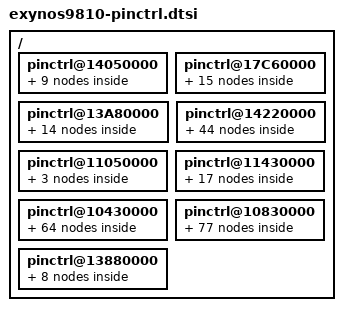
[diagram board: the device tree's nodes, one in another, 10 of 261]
/*
 * Samsung's Exynos9810 SoC pin-mux and pin-config device tree source
 *
 * Copyright (c) 2017 Samsung Electronics Co., Ltd.
 *		http://www.samsung.com
 *
 * Samsung's Exynos9810 SoC pin-mux and pin-config options are listed as device
 * tree nodes are listed in this file.
 *
 * This program is free software; you can redistribute it and/or modify
 * it under the terms of the GNU General Public License version 2 as
 * published by the Free Software Foundation.
*/

/ {
	/* ALIVE */
	pinctrl@14050000 {
		gpa0: gpa0 {
			gpio-controller;
			#gpio-cells = <2>;

			interrupt-controller;
			#interrupt-cells = <3>;
			interrupt-parent = <&gic>;
			interrupts = <0 36 0>, <0 37 0>, <0 38 0>, <0 39 0>,
				     <0 40 0>, <0 41 0>, <0 42 0>, <0 43 0>;
		};

		gpa1: gpa1 {
			gpio-controller;
			#gpio-cells = <2>;

			interrupt-controller;
			#interrupt-cells = <3>;
			interrupt-parent = <&gic>;
			interrupts = <0 44 0>, <0 45 0>, <0 46 0>, <0 47 0>,
				     <0 48 0>, <0 49 0>, <0 50 0>, <0 51 0>;
		};

		gpa2: gpa2 {
			gpio-controller;
			#gpio-cells = <2>;

			interrupt-controller;
			#interrupt-cells = <3>;
			interrupt-parent = <&gic>;
			interrupts = <0 52 0>, <0 53 0>, <0 54 0>, <0 55 0>,
				     <0 56 0>, <0 57 0>, <0 58 0>, <0 59 0>;
		};

		gpa3: gpa3 {
			gpio-controller;
			#gpio-cells = <2>;

			interrupt-controller;
			#interrupt-cells = <3>;
			interrupt-parent = <&gic>;
			interrupts = <0 60 0>, <0 61 0>, <0 62 0>, <0 63 0>,
				     <0 64 0>, <0 65 0>, <0 66 0>, <0 67 0>;
		};

		gpq0: gpq0 {
			gpio-controller;
			#gpio-cells = <2>;

			interrupt-controller;
			#interrupt-cells = <2>;
		};

		gpa4: gpa4 {
			gpio-controller;
			#gpio-cells = <2>;

			interrupt-controller;
			#interrupt-cells = <3>;
			interrupt-parent = <&gic>;
			interrupts = <0 INTREQ__EINT32 0>, <0 INTREQ__EINT33 0>;
		};

		speedy_bus: speedy-bus {
			samsung,pins = "gpq0-4";
			samsung,pin-function = <2>;
			samsung,pin-pud = <3>;
			samsung,pin-drv = <0>;
		};

		uart1_bus_single: uart1-bus {
			samsung,pins = "gpq0-3", "gpq0-2", "gpq0-1", "gpq0-0";
			samsung,pin-function = <2>;
			samsung,pin-pud = <0>;
		};

		uart1_bus_rts: uart1-bus-rts {
			samsung,pins = "gpq0-2";
			samsung,pin-function = <1>;
			samsung,pin-pud = <0>;
			samsung,pin-val = <1>;
		};

	};

	/* AUD */
	pinctrl@17C60000 {
		gpb0: gpb0 {
			gpio-controller;
			#gpio-cells = <2>;

			interrupt-controller;
			#interrupt-cells = <2>;
		};

		gpb1: gpb1 {
			gpio-controller;
			#gpio-cells = <2>;

			interrupt-controller;
			#interrupt-cells = <2>;
		};

		gpb2: gpb2 {
			gpio-controller;
			#gpio-cells = <2>;

			interrupt-controller;
			#interrupt-cells = <2>;
		};

		aud_codec_mclk: aud-codec-mclk {
			samsung,pins = "gpb0-0";
			samsung,pin-function = <2>;
			samsung,pin-pud = <1>;
		};

		aud_codec_mclk_idle: aud-codec-mclk-idle {
			samsung,pins = "gpb0-0";
			samsung,pin-function = <0>;
			samsung,pin-pud = <1>;
		};

		aud_i2s0_bus: aud-i2s0-bus {
			samsung,pins = "gpb0-1", "gpb0-2", "gpb0-3", "gpb0-4";
			samsung,pin-function = <2>;
			samsung,pin-pud = <1>;
		};

		aud_i2s0_idle: aud-i2s0-idle {
			samsung,pins = "gpb0-1", "gpb0-2", "gpb0-3", "gpb0-4";
			samsung,pin-function = <0>;
			samsung,pin-pud = <1>;
		};

		aud_i2s1_bus: aud-i2s1-bus {
			samsung,pins = "gpb1-0", "gpb1-1", "gpb1-2", "gpb1-3";
			samsung,pin-function = <2>;
			samsung,pin-pud = <1>;
		};

		aud_i2s1_idle: aud-i2s1-idle {
			samsung,pins = "gpb1-0", "gpb1-1", "gpb1-2", "gpb1-3";
			samsung,pin-function = <0>;
			samsung,pin-pud = <1>;
		};

		aud_i2s2_bus: aud-i2s2-bus {
			samsung,pins = "gpb1-4", "gpb1-5", "gpb1-6", "gpb1-7";
			samsung,pin-function = <2>;
			samsung,pin-pud = <1>;
		};

		aud_i2s2_idle: aud-i2s2-idle {
			samsung,pins = "gpb1-4", "gpb1-5", "gpb1-6", "gpb1-7";
			samsung,pin-function = <0>;
			samsung,pin-pud = <1>;
		};

		aud_dsd_bus: aud-dsd-bus {
			samsung,pins = "gpb1-4", "gpb1-5", "gpb1-6";
			samsung,pin-function = <3>;
			samsung,pin-pud = <1>;
		};

		aud_dsd_idle: aud-dsd-idle {
			samsung,pins = "gpb1-4", "gpb1-5", "gpb1-6";
			samsung,pin-function = <0>;
			samsung,pin-pud = <1>;
		};

		aud_i2s3_bus: aud-i2s3_bus {
			samsung,pins = "gpb2-0", "gpb2-1", "gpb2-2", "gpb2-3";
			samsung,pin-function = <2>;
			samsung,pin-pud = <1>;
		};

		aud_i2s3_idle: aud-i2s3-idle {
			samsung,pins = "gpb2-0", "gpb2-1", "gpb2-2", "gpb2-3";
			samsung,pin-function = <0>;
			samsung,pin-pud = <1>;
		};
	};

	/* CHUB */
	pinctrl@13A80000 {
		gph0: gph0 {
			gpio-controller;
			#gpio-cells = <2>;

			interrupt-controller;
			#interrupt-cells = <2>;
		};

		gph1: gph1 {
			gpio-controller;
			#gpio-cells = <2>;

			interrupt-controller;
			#interrupt-cells = <2>;
		};

		/* USI_CHUB 00 */
		hsi2c42_bus: hsi2c42-bus {
			samsung,pins = "gph0-0", "gph0-1";
			samsung,pin-function = <2>;
			samsung,pin-pud = <0>;
			samsung,pin-drv = <0>;
		};

		/* USI_CHUB00_I2C */
		hsi2c43_bus: hsi2c43-bus {
			samsung,pins = "gph0-2", "gph0-3";
			samsung,pin-function = <3>;
			samsung,pin-pud = <0>;
			samsung,pin-drv = <0>;
		};

		/* USI_CHUB 01 */
		hsi2c44_bus: hsi2c44-bus {
			samsung,pins = "gph0-4", "gph0-5";
			samsung,pin-function = <2>;
			samsung,pin-pud = <0>;
			samsung,pin-drv = <0>;
		};

		/* USI_CHUB01_I2C */
		hsi2c45_bus: hsi2c45-bus {
			samsung,pins = "gph0-6", "gph0-7";
			samsung,pin-function = <3>;
			samsung,pin-pud = <0>;
			samsung,pin-drv = <0>;
		};

		/* USI_CHUB00_UART */
		uart21_bus_single: uart21-bus {
			samsung,pins = "gph0-0", "gph0-1", "gph0-2", "gph-3";
			samsung,pin-function = <2>;
			samsung,pin-pud = <0>;
		};

		/* USI_CHUB01_UART */
		uart22_bus_single: uart22-bus {
			samsung,pins = "gph0-4", "gph0-5", "gph0-6", "gph-7";
			samsung,pin-function = <2>;
			samsung,pin-pud = <0>;
		};

		/* SPI USI_CHUB00 */
		spi20_bus: spi20-bus {
			samsung,pins = "gph0-0", "gph0-1", "gph0-2";
			samsung,pin-function = <2>;
			samsung,pin-pud = <3>;
			samsung,pin-drv = <0>;
		};

		spi20_cs: spi20-cs {
			samsung,pins = "gph0-3";
			samsung,pin-function = <1>;
			samsung,pin-pud = <3>;
			samsung,pin-drv = <0>;
		};

		spi20_cs_func: spi20-cs-func {
			samsung,pins = "gph0-3";
			samsung,pin-function = <2>;
			samsung,pin-pud = <3>;
			samsung,pin-drv = <0>;
		};

		/* SPI USI_CHUB01 */
		spi21_bus: spi21-bus {
			samsung,pins = "gph0-4", "gph0-5", "gph0-6";
			samsung,pin-function = <2>;
			samsung,pin-pud = <3>;
			samsung,pin-drv = <0>;
		};

		spi21_cs: spi21-cs {
			samsung,pins = "gph0-7";
			samsung,pin-function = <1>;
			samsung,pin-pud = <3>;
			samsung,pin-drv = <0>;
		};

		spi21_cs_func: spi21-cs-func {
			samsung,pins = "gph0-7";
			samsung,pin-function = <2>;
			samsung,pin-pud = <3>;
			samsung,pin-drv = <0>;
		};
	};

	/* CMGP */
	pinctrl@14220000 {
		gpm0: gpm0 {
			gpio-controller;
			#gpio-cells = <2>;

			interrupt-controller;
			#interrupt-cells = <3>;
			interrupt-parent = <&gic>;
			interrupts = <0 9 0>;
		};

		gpm1: gpm1 {
			gpio-controller;
			#gpio-cells = <2>;

			interrupt-controller;
			#interrupt-cells = <3>;
			interrupt-parent = <&gic>;
			interrupts = <0 10 0>;
		};

		gpm2: gpm2 {
			gpio-controller;
			#gpio-cells = <2>;

			interrupt-controller;
			#interrupt-cells = <3>;
			interrupt-parent = <&gic>;
			interrupts = <0 11 0>;
		};

		gpm3: gpm3 {
			gpio-controller;
			#gpio-cells = <2>;

			interrupt-controller;
			#interrupt-cells = <3>;
			interrupt-parent = <&gic>;
			interrupts = <0 12 0>;
		};

		gpm4: gpm4 {
			gpio-controller;
			#gpio-cells = <2>;

			interrupt-controller;
			#interrupt-cells = <3>;
			interrupt-parent = <&gic>;
			interrupts = <0 13 0>;
		};

		gpm5: gpm5 {
			gpio-controller;
			#gpio-cells = <2>;

			interrupt-controller;
			#interrupt-cells = <3>;
			interrupt-parent = <&gic>;
			interrupts = <0 14 0>;
		};

		gpm6: gpm6 {
			gpio-controller;
			#gpio-cells = <2>;

			interrupt-controller;
			#interrupt-cells = <3>;
			interrupt-parent = <&gic>;
			interrupts = <0 15 0>;
		};

		gpm7: gpm7 {
			gpio-controller;
			#gpio-cells = <2>;

			interrupt-controller;
			#interrupt-cells = <3>;
			interrupt-parent = <&gic>;
			interrupts = <0 16 0>;
		};

		gpm10: gpm10 {
			gpio-controller;
			#gpio-cells = <2>;

			interrupt-controller;
			#interrupt-cells = <3>;
			interrupt-parent = <&gic>;
			interrupts = <0 17 0>;
		};

		gpm11: gpm11 {
			gpio-controller;
			#gpio-cells = <2>;


			interrupt-controller;
			#interrupt-cells = <3>;
			interrupt-parent = <&gic>;
			interrupts = <0 18 0>;
		};

		gpm12: gpm12 {
			gpio-controller;
			#gpio-cells = <2>;

			interrupt-controller;
			#interrupt-cells = <3>;
			interrupt-parent = <&gic>;
			interrupts = <0 19 0>;
		};

		gpm13: gpm13 {
			gpio-controller;
			#gpio-cells = <2>;

			interrupt-controller;
			#interrupt-cells = <3>;
			interrupt-parent = <&gic>;
			interrupts = <0 20 0>;
		};

		gpm14: gpm14 {
			gpio-controller;
			#gpio-cells = <2>;

			interrupt-controller;
			#interrupt-cells = <3>;
			interrupt-parent = <&gic>;
			interrupts = <0 21 0>;
		};

		gpm15: gpm15 {
			gpio-controller;
			#gpio-cells = <2>;

			interrupt-controller;
			#interrupt-cells = <3>;
			interrupt-parent = <&gic>;
			interrupts = <0 22 0>;
		};

		gpm16: gpm16 {
			gpio-controller;
			#gpio-cells = <2>;

			interrupt-controller;
			#interrupt-cells = <3>;
			interrupt-parent = <&gic>;
			interrupts = <0 23 0>;
		};

		gpm17: gpm17 {
			gpio-controller;
			#gpio-cells = <2>;

			interrupt-controller;
			#interrupt-cells = <3>;
			interrupt-parent = <&gic>;
			interrupts = <0 24 0>;
		};

		gpm40: gpm40 {
			gpio-controller;
			#gpio-cells = <2>;


			interrupt-controller;
			#interrupt-cells = <3>;
			interrupt-parent = <&gic>;
			interrupts = <0 25 0>;
		};

		gpm41: gpm41 {
			gpio-controller;
			#gpio-cells = <2>;

			interrupt-controller;
			#interrupt-cells = <3>;
			interrupt-parent = <&gic>;
			interrupts = <0 26 0>;
		};

		gpm42: gpm42 {
			gpio-controller;
			#gpio-cells = <2>;

			interrupt-controller;
			#interrupt-cells = <3>;
			interrupt-parent = <&gic>;
			interrupts = <0 27 0>;
		};

		gpm43: gpm43 {
			gpio-controller;
			#gpio-cells = <2>;

			interrupt-controller;
			#interrupt-cells = <3>;
			interrupt-parent = <&gic>;
			interrupts = <0 28 0>;
		};

		/* USI_CMGP00 */
		hsi2c34_bus: hsi2c34-bus {
			samsung,pins = "gpm0-0", "gpm1-0";
			samsung,pin-function = <2>;
			samsung,pin-pud = <0>;
			samsung,pin-drv = <0>;
		};

		/* USI_CMGP00_I2C */
		hsi2c35_bus: hsi2c35-bus {
			samsung,pins = "gpm2-0", "gpm3-0";
			samsung,pin-function = <3>;
			samsung,pin-pud = <0>;
			samsung,pin-drv = <0>;
		};

		/* USI_CMGP01 */
		hsi2c36_bus: hsi2c36-bus {
			samsung,pins = "gpm4-0", "gpm5-0";
			samsung,pin-function = <2>;
			samsung,pin-pud = <0>;
			samsung,pin-drv = <0>;
		};

		/* USI_CMGP01_I2C */
		hsi2c37_bus: hsi2c37-bus {
			samsung,pins = "gpm6-0", "gpm7-0";
			samsung,pin-function = <3>;
			samsung,pin-pud = <0>;
			samsung,pin-drv = <0>;
		};

		/* USI_CMGP02 */
		hsi2c38_bus: hsi2c38-bus {
			samsung,pins = "gpm10-0", "gpm11-0";
			samsung,pin-function = <2>;
			samsung,pin-pud = <0>;
			samsung,pin-drv = <0>;
		};

		/* USI_CMGP02_I2C */
		hsi2c39_bus: hsi2c39-bus {
			samsung,pins = "gpm12-0", "gpm13-0";
			samsung,pin-function = <3>;
			samsung,pin-pud = <0>;
			samsung,pin-drv = <0>;
		};

		/* USI_CMGP03 */
		hsi2c40_bus: hsi2c40-bus {
			samsung,pins = "gpm14-0", "gpm15-0";
			samsung,pin-function = <2>;
			samsung,pin-pud = <0>;
			samsung,pin-drv = <0>;
		};

		/* USI_CMGP03_I2C */
		hsi2c41_bus: hsi2c41-bus {
			samsung,pins = "gpm16-0", "gpm17-0";
			samsung,pin-function = <3>;
			samsung,pin-pud = <0>;
			samsung,pin-drv = <0>;
		};

		/* SPI USI_CMGP00 */
		spi16_bus: spi16-bus {
			samsung,pins = "gpm0-0", "gpm1-0", "gpm2-0";
			samsung,pin-function = <2>;
			samsung,pin-pud = <3>;
			samsung,pin-drv = <0>;
		};

		spi16_cs: spi16-cs {
			samsung,pins = "gpm3-0";
			samsung,pin-function = <1>;
			samsung,pin-pud = <3>;
			samsung,pin-drv = <0>;
		};

		spi16_cs_func: spi16-cs-func {
			samsung,pins = "gpm3-0";
			samsung,pin-function = <2>;
			samsung,pin-pud = <3>;
			samsung,pin-drv = <0>;
		};

		/* SPI USI_CMGP01 */
		spi17_bus: spi17-bus {
			samsung,pins = "gpm4-0", "gpm5-0", "gpm6-0";
			samsung,pin-function = <2>;
			samsung,pin-pud = <3>;
			samsung,pin-drv = <0>;
		};

		spi17_cs: spi17-cs {
			samsung,pins = "gpm7-0";
			samsung,pin-function = <1>;
			samsung,pin-pud = <3>;
			samsung,pin-drv = <0>;
		};

		spi17_cs_func: spi17-cs-func {
			samsung,pins = "gpm7-0";
			samsung,pin-function = <2>;
			samsung,pin-pud = <3>;
			samsung,pin-drv = <0>;
		};

		/* SPI USI_CMGP02 */
		spi18_bus: spi18-bus {
			samsung,pins = "gpm10-0", "gpm11-0", "gpm12-0";
			samsung,pin-function = <2>;
			samsung,pin-pud = <3>;
			samsung,pin-drv = <0>;
		};

		spi18_cs: spi18-cs {
			samsung,pins = "gpm13-0";
			samsung,pin-function = <1>;
			samsung,pin-pud = <3>;
			samsung,pin-drv = <0>;
		};

		spi18_cs_func: spi18-cs-func {
			samsung,pins = "gpm13-0";
			samsung,pin-function = <2>;
			samsung,pin-pud = <3>;
			samsung,pin-drv = <0>;
		};

		/* SPI USI_CMGP03 */
		spi19_bus: spi19-bus {
			samsung,pins = "gpm14-0", "gpm15-0", "gpm16-0";
			samsung,pin-function = <2>;
			samsung,pin-pud = <3>;
			samsung,pin-drv = <0>;
		};

		spi19_cs: spi19-cs {
			samsung,pins = "gpm17-0";
			samsung,pin-function = <1>;
			samsung,pin-pud = <3>;
			samsung,pin-drv = <0>;
		};

		spi19_cs_func: spi19-cs-func {
			samsung,pins = "gpm17-0";
			samsung,pin-function = <2>;
			samsung,pin-pud = <3>;
			samsung,pin-drv = <0>;
		};

		/* USI_CMGP00_UART */
		uart17_bus_single: uart17-bus {
			samsung,pins = "gpm0-0", "gpm1-0", "gpm2-0", "gpm3-0";
			samsung,pin-function = <2>;
			samsung,pin-pud = <0>;
		};

		/* USI_CMGP01_UART */
		uart18_bus_single: uart18-bus {
			samsung,pins = "gpm4-0", "gpm5-0", "gpm6-0", "gpm7-0";
			samsung,pin-function = <2>;
			samsung,pin-pud = <0>;
		};

		/* USI_CMGP02_UART */
		uart19_bus_single: uart19-bus {
			samsung,pins = "gpm10-0", "gpm11-0", "gpm12-0", "gpm13-0";
			samsung,pin-function = <2>;
			samsung,pin-pud = <0>;
		};

		/* USI_CMGP03_UART */
		uart20_bus_single: uart20-bus {
			samsung,pins = "gpm14-0", "gpm15-0", "gpm16-0", "gpm17-0";
			samsung,pin-function = <2>;
			samsung,pin-pud = <0>;
		};

	};

	/* FSYS0 */
	pinctrl@11050000 {
		gpf0: gpf0 {
			gpio-controller;
			#gpio-cells = <2>;

			interrupt-controller;
			#interrupt-cells = <2>;
		};

		ufs_rst_n: ufs-rst-n {
			samsung,pins = "gpf0-1";
			samsung,pin-function = <2>;
			samsung,pin-pud = <0>;
			samsung,pin-con-pdn = <3>;
		};

		ufs_refclk_out: ufs-refclk-out {
			samsung,pins = "gpf0-0";
			samsung,pin-function = <2>;
			samsung,pin-pud = <0>;
			samsung,pin-con-pdn = <3>;
		};
	};

	/* FSYS1 */
	pinctrl@11430000 {
		gpf1: gpf1 {
			gpio-controller;
			#gpio-cells = <2>;

			interrupt-controller;
			#interrupt-cells = <2>;
		};
		gpf2: gpf2 {
			gpio-controller;
			#gpio-cells = <2>;

			interrupt-controller;
			#interrupt-cells = <2>;
		};

		sd2_clk: sd2-clk {
			samsung,pins = "gpf1-0";
			samsung,pin-function = <2>;
			samsung,pin-pud = <0>;
			samsung,pin-drv = <2>;
		};

		sd2_cmd: sd2-cmd {
			samsung,pins = "gpf1-1";
			samsung,pin-function = <2>;
			samsung,pin-pud = <3>;
			samsung,pin-drv = <2>;
		};

		sd2_bus1: sd2-bus-width1 {
			samsung,pins = "gpf1-2";
			samsung,pin-function = <2>;
			samsung,pin-pud = <3>;
			samsung,pin-drv = <2>;
		};

		sd2_bus4: sd2-bus-width4 {
			samsung,pins = "gpf1-3", "gpf1-4", "gpf1-5";
			samsung,pin-function = <2>;
			samsung,pin-pud = <3>;
			samsung,pin-drv = <2>;
		};

		sd2_clk_fast_slew_rate_1x: sd2-clk_fast_slew_rate_1x {
			samsung,pins = "gpf1-0";
			samsung,pin-function = <2>;
			samsung,pin-pud = <0>;
			samsung,pin-drv = <0>;
		};

		sd2_clk_fast_slew_rate_1_5x: sd2-clk_fast_slew_rate_1_5x {
			samsung,pins = "gpf1-0";
			samsung,pin-function = <2>;
			samsung,pin-pud = <0>;
			samsung,pin-drv = <1>;
		};

		sd2_clk_fast_slew_rate_2x: sd2-clk_fast_slew_rate_2x {
			samsung,pins = "gpf1-0";
			samsung,pin-function = <2>;
			samsung,pin-pud = <0>;
			samsung,pin-drv = <2>;
		};

		sd2_clk_fast_slew_rate_2_5x: sd2-clk_fast_slew_rate_2_5x {
			samsung,pins = "gpf1-0";
			samsung,pin-function = <2>;
			samsung,pin-pud = <0>;
			samsung,pin-drv = <3>;
		};

		sd2_clk_fast_slew_rate_3x: sd2-clk_fast_slew_rate_3x {
			samsung,pins = "gpf1-0";
			samsung,pin-function = <2>;
			samsung,pin-pud = <0>;
			samsung,pin-drv = <4>;
		};

		sd2_clk_fast_slew_rate_4x: sd2-clk_fast_slew_rate_4x {
			samsung,pins = "gpf1-0";
			samsung,pin-function = <2>;
			samsung,pin-pud = <0>;
			samsung,pin-drv = <5>;
		};

		pcie0_clkreq: pcie0_clkreq {
			samsung,pins = "gpf2-0";
			samsung,pin-function = <2>;
			samsung,pin-pud = <3>;
			samsung,pin-drv = <3>;
			samsung,pin-con-pdn = <3>;
			samsung,pin-pud-pdn = <3>;
		};

		pcie0_clkreq_output: pcie0_clkreq_output {
			samsung,pins = "gpf2-0";
			samsung,pin-function = <1>;
			samsung,pin-pud = <3>;
			samsung,pin-drv = <3>;
			samsung,pin-con-pdn = <3>;
			samsung,pin-pud-pdn = <3>;
			samsung,pin-val = <1>;
		};

		pcie0_perst: pcie0_perst {
			samsung,pins = "gpf2-2";
			samsung,pin-function = <1>;
			samsung,pin-drv = <3>;
			samsung,pin-con-pdn = <3>;
		};

		pcie1_clkreq: pcie1_clkreq {
			samsung,pins = "gpf2-3";
			samsung,pin-function = <2>;
			samsung,pin-pud = <3>;
			samsung,pin-drv = <3>;
			samsung,pin-con-pdn = <3>;
			samsung,pin-pud-pdn = <3>;
		};

		pcie1_perst: pcie1_perst {
			samsung,pins = "gpf2-5";
			samsung,pin-function = <1>;
			samsung,pin-drv = <3>;
			samsung,pin-con-pdn = <3>;
		};

	};

	/* PERIC0 */
	pinctrl@10430000 {
		gpp0: gpp0 {
			gpio-controller;
			#gpio-cells = <2>;

			interrupt-controller;
			#interrupt-cells = <2>;
		};

		gpp1: gpp1 {
			gpio-controller;
			#gpio-cells = <2>;

			interrupt-controller;
			#interrupt-cells = <2>;
		};

		gpp2: gpp2 {
			gpio-controller;
			#gpio-cells = <2>;

			interrupt-controller;
			#interrupt-cells = <2>;
		};

		gpp3: gpp3 {
			gpio-controller;
			#gpio-cells = <2>;

			interrupt-controller;
			#interrupt-cells = <2>;
		};

		gpg0: gpg0 {
			gpio-controller;
			#gpio-cells = <2>;

			interrupt-controller;
			#interrupt-cells = <2>;
		};

		gpg1: gpg1 {
			gpio-controller;
			#gpio-cells = <2>;

			interrupt-controller;
			#interrupt-cells = <2>;
		};

		gpg2: gpg2 {
			gpio-controller;
			#gpio-cells = <2>;

			interrupt-controller;
			#interrupt-cells = <2>;
		};

		cfg_wlanen: cfg_wlanen {
			samsung,pins = "gpg1-0";
			samsung,pin-function = <1>;
			samsung,pin-drv = <3>;
			samsung,pin-con-pdn = <3>;
		};

		/* USI_PERIC0_UART_DBG */
		uart0_bus: uart0-bus {
			samsung,pins = "gpp3-2", "gpp3-3";
			samsung,pin-function = <3>;
			samsung,pin-pud = <0>;
		};

		/* PERIC0 USI00 */
		hsi2c4_bus: hsi2c4-bus {
			samsung,pins = "gpp0-0", "gpp0-1";
			samsung,pin-function = <2>;
			samsung,pin-pud = <0>;
			samsung,pin-drv = <0>;
		};

		/* PERIC0 USI00_I2C */
		hsi2c5_bus: hsi2c5-bus {
			samsung,pins = "gpp0-2", "gpp0-3";
			samsung,pin-function = <3>;
			samsung,pin-pud = <0>;
			samsung,pin-drv = <0>;
		};

		/* PERIC0 USI01 */
		hsi2c6_bus: hsi2c6-bus {
			samsung,pins = "gpp0-4", "gpp0-5";
			samsung,pin-function = <2>;
			samsung,pin-pud = <0>;
			samsung,pin-drv = <0>;
		};

		/* PERIC0 USI01_I2C */
		hsi2c7_bus: hsi2c7-bus {
			samsung,pins = "gpp0-6", "gpp0-7";
			samsung,pin-function = <3>;
			samsung,pin-pud = <0>;
			samsung,pin-drv = <0>;
		};

		/* PERIC0 USI02 */
		hsi2c8_bus: hsi2c8-bus {
			samsung,pins = "gpp1-0", "gpp1-1";
			samsung,pin-function = <2>;
			samsung,pin-pud = <0>;
			samsung,pin-drv = <0>;
		};

		/* PERIC0 USI02_I2C */
		hsi2c9_bus: hsi2c9-bus {
			samsung,pins = "gpp1-2", "gpp1-3";
			samsung,pin-function = <3>;
			samsung,pin-pud = <0>;
			samsung,pin-drv = <0>;
		};

		/* PERIC0 USI03 */
		hsi2c10_bus: hsi2c10-bus {
			samsung,pins = "gpp1-4", "gpp1-5";
			samsung,pin-function = <2>;
			samsung,pin-pud = <0>;
			samsung,pin-drv = <0>;
		};

		/* PERIC0 USI03_I2C */
		hsi2c11_bus: hsi2c11-bus {
			samsung,pins = "gpp1-6", "gpp1-7";
			samsung,pin-function = <3>;
			samsung,pin-pud = <0>;
			samsung,pin-drv = <0>;
		};

		/* PERIC0 USI04 */
		hsi2c12_bus: hsi2c12-bus {
			samsung,pins = "gpp2-0", "gpp2-1";
			samsung,pin-function = <2>;
			samsung,pin-pud = <0>;
			samsung,pin-drv = <0>;
		};

		/* PERIC0 USI04_I2C */
		hsi2c13_bus: hsi2c13-bus {
			samsung,pins = "gpp2-2", "gpp1-3";
			samsung,pin-function = <3>;
			samsung,pin-pud = <0>;
			samsung,pin-drv = <0>;
		};

		/* PERIC0 USI05 */
		hsi2c14_bus: hsi2c14-bus {
			samsung,pins = "gpp2-4", "gpp2-5";
			samsung,pin-function = <2>;
			samsung,pin-pud = <0>;
			samsung,pin-drv = <0>;
		};

		/* PERIC0 USI05_I2C */
		hsi2c15_bus: hsi2c15-bus {
			samsung,pins = "gpp2-6", "gpp2-7";
			samsung,pin-function = <3>;
			samsung,pin-pud = <0>;
			samsung,pin-drv = <0>;
		};

		/* PERIC0 SMPL_WARN */
		smpl_warn: smpl_warn {
			samsung,pins = "gpg0-3";
			samsung,pin-function = <15>;
			samsung,pin-pud = <0>;
			samsung,pin-drv = <0>;
		};

		/* PERIC0 USI12 */
		hsi2c28_bus: hsi2c28-bus {
			samsung,pins = "gpg0-4", "gpg0-5";
			samsung,pin-function = <2>;
			samsung,pin-pud = <0>;
			samsung,pin-drv = <0>;
		};

		/* PERIC0 USI12_I2C */
		hsi2c29_bus: hsi2c29-bus {
			samsung,pins = "gpg0-6", "gpg0-7";
			samsung,pin-function = <3>;
			samsung,pin-pud = <0>;
			samsung,pin-drv = <0>;
		};

		/* PERIC0 USI13 */
		hsi2c30_bus: hsi2c30-bus {
			samsung,pins = "gpg1-0", "gpg1-1";
			samsung,pin-function = <2>;
			samsung,pin-pud = <0>;
			samsung,pin-drv = <0>;
		};

		/* PERIC0 USI13_I2C */
		hsi2c31_bus: hsi2c31-bus {
			samsung,pins = "gpg1-2", "gpg1-3";
			samsung,pin-function = <3>;
			samsung,pin-pud = <0>;
			samsung,pin-drv = <0>;
		};

		/* PERIC0 USI14 */
		hsi2c32_bus: hsi2c32-bus {
			samsung,pins = "gpg1-4", "gpg1-5";
			samsung,pin-function = <2>;
			samsung,pin-pud = <0>;
			samsung,pin-drv = <0>;
		};

		/* PERIC0 USI14_I2C */
		hsi2c33_bus: hsi2c33-bus {
			samsung,pins = "gpg1-6", "gpg1-7";
			samsung,pin-function = <3>;
			samsung,pin-pud = <0>;
			samsung,pin-drv = <0>;
		};

		/* SPI USI_PERIC0_USI00_SPI */
		spi1_bus: spi1-bus {
			samsung,pins = "gpp0-2", "gpp0-1", "gpp0-0";
			samsung,pin-function = <2>;
			samsung,pin-pud = <3>;
			samsung,pin-drv = <0>;
		};

		spi1_cs: spi1-cs {
			samsung,pins = "gpp0-3";
			samsung,pin-function = <1>;
			samsung,pin-pud = <3>;
			samsung,pin-drv = <0>;
		};

		spi1_cs_func: spi1-cs-func {
			samsung,pins = "gpp0-3";
			samsung,pin-function = <2>;
			samsung,pin-pud = <3>;
			samsung,pin-drv = <0>;
		};

		/* PERIC0 USI01_SPI */
		spi2_bus: spi2-bus {
			samsung,pins = "gpp0-6", "gpp0-5", "gpp0-4";
			samsung,pin-function = <2>;
			samsung,pin-pud = <0>;
			samsung,pin-drv = <0>;
		};

		spi2_cs: spi2-cs {
			samsung,pins = "gpp0-7";
			samsung,pin-function = <1>;
			samsung,pin-pud = <3>;
			samsung,pin-drv = <0>;
		};

		spi2_cs_func: spi2-cs-func {
			samsung,pins = "gpp0-7";
			samsung,pin-function = <2>;
			samsung,pin-pud = <3>;
			samsung,pin-drv = <0>;
		};

		/* PERIC0 USI02_SPI */
		spi3_bus: spi3-bus {
			samsung,pins = "gpp1-2", "gpp1-1", "gpp1-0";
			samsung,pin-function = <2>;
			samsung,pin-pud = <3>;
			samsung,pin-drv = <0>;
		};

		spi3_cs: spi3-cs {
			samsung,pins = "gpp1-3";
			samsung,pin-function = <1>;
			samsung,pin-pud = <3>;
			samsung,pin-drv = <0>;
		};

		spi3_cs_func: spi3-cs-func {
			samsung,pins = "gpp1-3";
			samsung,pin-function = <2>;
			samsung,pin-pud = <3>;
			samsung,pin-drv = <0>;
		};

		/* PERIC0 USI03_SPI */
		spi4_bus: spi4-bus {
			samsung,pins = "gpp1-4", "gpp1-5", "gpp1-6";
			samsung,pin-function = <2>;
			samsung,pin-pud = <3>;
			samsung,pin-drv = <0>;
		};

		spi4_cs: spi4-cs {
			samsung,pins = "gpp1-7";
			samsung,pin-function = <1>;
			samsung,pin-pud = <3>;
			samsung,pin-drv = <0>;
		};

		spi4_cs_func: spi4-cs-func {
			samsung,pins = "gpp1-7";
			samsung,pin-function = <2>;
			samsung,pin-pud = <3>;
			samsung,pin-drv = <0>;
		};

		/* PERIC0 USI04_SPI */
		spi5_bus: spi5-bus {
			samsung,pins = "gpp2-2", "gpp2-1", "gpp2-0";
			samsung,pin-function = <2>;
			samsung,pin-pud = <3>;
			samsung,pin-drv = <0>;
		};

		spi5_cs: spi5-cs {
			samsung,pins = "gpp2-3";
			samsung,pin-function = <1>;
			samsung,pin-pud = <3>;
			samsung,pin-drv = <0>;
		};

		spi5_cs_func: spi5-cs-func {
			samsung,pins = "gpp2-3";
			samsung,pin-function = <2>;
			samsung,pin-pud = <3>;
			samsung,pin-drv = <0>;
		};

		/* PERIC0 USI05_SPI */
		spi6_bus: spi6-bus {
			samsung,pins = "gpp2-6", "gpp2-5", "gpp2-4";
			samsung,pin-function = <2>;
			samsung,pin-pud = <3>;
			samsung,pin-drv = <0>;
		};

		spi6_cs: spi6-cs {
			samsung,pins = "gpp2-7";
			samsung,pin-function = <1>;
			samsung,pin-pud = <3>;
			samsung,pin-drv = <0>;
		};

		spi6_cs_func: spi6-cs-func {
			samsung,pins = "gpp2-7";
			samsung,pin-function = <2>;
			samsung,pin-pud = <3>;
			samsung,pin-drv = <0>;
		};

		/* PERIC0 USI12_SPI */
		spi13_bus: spi13-bus {
			samsung,pins = "gpg0-4", "gpg0-5", "gpg0-6";
			samsung,pin-function = <2>;
			samsung,pin-pud = <3>;
			samsung,pin-drv = <0>;
		};

		spi13_cs: spi13-cs {
			samsung,pins = "gpg0-7";
			samsung,pin-function = <1>;
			samsung,pin-pud = <3>;
			samsung,pin-drv = <0>;
		};

		spi13_cs_func: spi13-cs-func {
			samsung,pins = "gpg0-7";
			samsung,pin-function = <2>;
			samsung,pin-pud = <3>;
			samsung,pin-drv = <0>;
		};

		/* PERIC0 USI13_SPI */
		spi14_bus: spi14-bus {
			samsung,pins = "gpg1-2", "gpg1-1", "gpg1-0";
			samsung,pin-function = <2>;
			samsung,pin-pud = <3>;
			samsung,pin-drv = <0>;
		};

		spi14_cs: spi14-cs {
			samsung,pins = "gpg1-3";
			samsung,pin-function = <1>;
			samsung,pin-pud = <3>;
			samsung,pin-drv = <0>;
		};

		spi14_cs_func: spi14-cs-func {
			samsung,pins = "gpg1-3";
			samsung,pin-function = <2>;
			samsung,pin-pud = <3>;
			samsung,pin-drv = <0>;
		};

		/* PERIC0 USI14_SPI */
		spi15_bus: spi15-bus {
			samsung,pins = "gpg1-4", "gpg1-5", "gpg1-6";
			samsung,pin-function = <2>;
			samsung,pin-pud = <3>;
			samsung,pin-drv = <0>;
		};

		spi15_cs: spi15-cs {
			samsung,pins = "gpg1-7";
			samsung,pin-function = <1>;
			samsung,pin-pud = <3>;
			samsung,pin-drv = <0>;
		};

		spi15_cs_func: spi15-cs-func {
			samsung,pins = "gpg1-7";
			samsung,pin-function = <2>;
			samsung,pin-pud = <3>;
			samsung,pin-drv = <0>;
		};

		/* USI_PERIC0_USI00_UART */
		uart2_bus_single: uart2-bus {
			samsung,pins = "gpp0-0", "gpp0-1", "gpp0-2", "gpp0-3";
			samsung,pin-function = <2>;
			samsung,pin-pud = <0>;
		};

		/* USI_PERIC0_USI01_UART */
		uart3_bus_single: uart3-bus {
			samsung,pins = "gpp0-4", "gpp0-5", "gpp0-6", "gpp0-7";
			samsung,pin-function = <2>;
			samsung,pin-pud = <0>;
		};

		/* USI_PERIC0_USI02_UART */
		uart4_bus_single: uart4-bus {
			samsung,pins = "gpp1-0", "gpp1-1", "gpp1-2", "gpp1-3";
			samsung,pin-function = <2>;
			samsung,pin-pud = <0>;
		};

		/* USI_PERIC0_USI03_UART */
		uart5_bus_single: uart5-bus {
			samsung,pins = "gpp1-4", "gpp1-5", "gpp1-6", "gpp1-7";
			samsung,pin-function = <2>;
			samsung,pin-pud = <0>;
		};

		/* USI_PERIC0_USI04_UART */
		uart6_bus_single: uart6-bus {
			samsung,pins = "gpp2-0", "gpp2-1", "gpp2-2", "gpp2-3";
			samsung,pin-function = <2>;
			samsung,pin-pud = <0>;
		};

		/* USI_PERIC0_USI05_UART */
		uart7_bus_single: uart7-bus {
			samsung,pins = "gpp2-4", "gpp2-5", "gpp2-6", "gpp2-7";
			samsung,pin-function = <2>;
			samsung,pin-pud = <0>;
		};

		/* USI_PERIC0_USI12_UART */
		uart14_bus_single: uart14-bus {
			samsung,pins = "gpg0-4", "gpg0-5", "gpg0-6", "gpg0-7";
			samsung,pin-function = <2>;
			samsung,pin-pud = <0>;
		};

		/* USI_PERIC0_USI13_UART */
		uart15_bus_single: uart15-bus {
			samsung,pins = "gpg1-0", "gpg1-1", "gpg1-2", "gpg1-3";
			samsung,pin-function = <2>;
			samsung,pin-pud = <0>;
		};

		/* USI_PERIC0_USI14_UART */
		uart16_bus_single: uart16-bus {
			samsung,pins = "gpg1-4", "gpg1-5", "gpg1-6", "gpg1-7";
			samsung,pin-function = <2>;
			samsung,pin-pud = <0>;
		};
	};

	/* PERIC1 */
	pinctrl@10830000 {
		gpp4: gpp4 {
			gpio-controller;
			#gpio-cells = <2>;

			interrupt-controller;
			#interrupt-cells = <2>;
		};

		gpp5: gpp5 {
			gpio-controller;
			#gpio-cells = <2>;

			interrupt-controller;
			#interrupt-cells = <2>;
		};

		gpp6: gpp6 {
			gpio-controller;
			#gpio-cells = <2>;

			interrupt-controller;
			#interrupt-cells = <2>;
		};

		gpc0: gpc0 {
			gpio-controller;
			#gpio-cells = <2>;

			interrupt-controller;
			#interrupt-cells = <2>;
		};

		gpc1: gpc1 {
			gpio-controller;
			#gpio-cells = <2>;

			interrupt-controller;
			#interrupt-cells = <2>;
		};

		gpd0: gpd0 {
			gpio-controller;
			#gpio-cells = <2>;

			interrupt-controller;
			#interrupt-cells = <2>;
		};

		gpg3: gpg3 {
			gpio-controller;
			#gpio-cells = <2>;

			interrupt-controller;
			#interrupt-cells = <2>;
		};

		decon_f_te_on: decon_f_te_on {
			samsung,pins = "gpd0-0";
			samsung,pin-function = <0xf>;
		};

		decon_f_te_off: decon_f_te_off {
			samsung,pins = "gpd0-0";
			samsung,pin-function = <0>;
		};

		/* PERIC1 CAM0 */
		hsi2c0_bus: hsi2c0-bus {
			samsung,pins = "gpc0-0", "gpc0-1";
			samsung,pin-function = <2>;
			samsung,pin-pud = <3>;
			samsung,pin-drv = <0>;
		};

		hsi2c0_bus_in: hsi2c0-bus-in {
			samsung,pins = "gpc0-0", "gpc0-1";
			samsung,pin-function = <0>;
			samsung,pin-pud = <0>;
			samsung,pin-drv = <0>;
		};

		/* PERIC1 CAM1 */
		hsi2c1_bus: hsi2c1-bus {
			samsung,pins = "gpc0-2", "gpc0-3";
			samsung,pin-function = <2>;
			samsung,pin-pud = <3>;
			samsung,pin-drv = <0>;
		};

		hsi2c1_bus_in: hsi2c1-bus-in {
			samsung,pins = "gpc0-2", "gpc0-3";
			samsung,pin-function = <0>;
			samsung,pin-pud = <0>;
			samsung,pin-drv = <0>;
		};

		/* PERIC1 CAM2 */
		hsi2c2_bus: hsi2c2-bus {
			samsung,pins = "gpc0-4", "gpc0-5";
			samsung,pin-function = <2>;
			samsung,pin-pud = <3>;
			samsung,pin-drv = <0>;
		};

		hsi2c2_bus_in: hsi2c2-bus-in {
			samsung,pins = "gpc0-4", "gpc0-5";
			samsung,pin-function = <0>;
			samsung,pin-pud = <0>;
			samsung,pin-drv = <0>;
		};

		/* PERIC1 CAM3 */
		hsi2c3_bus: hsi2c3-bus {
			samsung,pins = "gpc0-6", "gpc0-7";
			samsung,pin-function = <2>;
			samsung,pin-pud = <3>;
			samsung,pin-drv = <0>;
		};

		hsi2c3_bus_in: hsi2c3-bus-in {
			samsung,pins = "gpc0-6", "gpc0-7";
			samsung,pin-function = <0>;
			samsung,pin-pud = <0>;
			samsung,pin-drv = <0>;
		};

		/* PERIC1 USI06 */
		hsi2c16_bus: hsi2c16-bus {
			samsung,pins = "gpp4-0", "gpp4-1";
			samsung,pin-function = <2>;
			samsung,pin-pud = <0>;
			samsung,pin-drv = <0>;
		};

		/* PERIC1 USI06_I2C */
		hsi2c17_bus: hsi2c17-bus {
			samsung,pins = "gpp4-2", "gpp4-3";
			samsung,pin-function = <3>;
			samsung,pin-pud = <0>;
			samsung,pin-drv = <0>;
		};

		/* PERIC1 USI07 */
		hsi2c18_bus: hsi2c18-bus {
			samsung,pins = "gpp4-4", "gpp4-5";
			samsung,pin-function = <2>;
			samsung,pin-pud = <0>;
			samsung,pin-drv = <0>;
		};

		/* PERIC1 USI07_I2C */
		hsi2c19_bus: hsi2c19-bus {
			samsung,pins = "gpp4-6", "gpp4-7";
			samsung,pin-function = <3>;
			samsung,pin-pud = <0>;
			samsung,pin-drv = <0>;
		};

		hsi2c19_bus_in: hsi2c19-bus-in {
			samsung,pins = "gpp4-6", "gpp4-7";
			samsung,pin-function = <0>;
			samsung,pin-pud = <0>;
			samsung,pin-drv = <0>;
		};

		/* PERIC1 USI08 */
		hsi2c20_bus: hsi2c20-bus {
			samsung,pins = "gpp5-0", "gpp5-1";
			samsung,pin-function = <2>;
			samsung,pin-pud = <0>;
			samsung,pin-drv = <0>;
		};

		/* PERIC1 USI08_I2C */
		hsi2c21_bus: hsi2c21-bus {
			samsung,pins = "gpp5-2", "gpp5-3";
			samsung,pin-function = <3>;
			samsung,pin-pud = <0>;
			samsung,pin-drv = <0>;
		};

		hsi2c21_bus_in: hsi2c21-bus-in {
			samsung,pins = "gpp5-2", "gpp5-3";
			samsung,pin-function = <0>;
			samsung,pin-pud = <0>;
			samsung,pin-drv = <0>;
		};

		/* PERIC1 USI09 */
		hsi2c22_bus: hsi2c22-bus {
			samsung,pins = "gpp5-4", "gpp5-5";
			samsung,pin-function = <2>;
			samsung,pin-pud = <0>;
			samsung,pin-drv = <0>;
		};

		hsi2c22_bus_in: hsi2c22-bus-in {
			samsung,pins = "gpp5-4", "gpp5-5";
			samsung,pin-function = <0>;
			samsung,pin-pud = <0>;
			samsung,pin-drv = <0>;
		};

		/* PERIC1 USI09_I2C */
		hsi2c23_bus: hsi2c23-bus {
			samsung,pins = "gpp5-6", "gpp5-7";
			samsung,pin-function = <3>;
			samsung,pin-pud = <0>;
			samsung,pin-drv = <0>;
		};

		/* PERIC1 USI10 */
		hsi2c24_bus: hsi2c24-bus {
			samsung,pins = "gpp6-0", "gpp6-1";
			samsung,pin-function = <2>;
			samsung,pin-pud = <0>;
			samsung,pin-drv = <0>;
		};

		/* PERIC1 USI10_I2C */
		hsi2c25_bus: hsi2c25-bus {
			samsung,pins = "gpp6-2", "gpp6-3";
			samsung,pin-function = <3>;
			samsung,pin-pud = <0>;
			samsung,pin-drv = <0>;
		};

		/* PERIC1 USI11 */
		hsi2c26_bus: hsi2c26-bus {
			samsung,pins = "gpg3-3", "gpg3-4";
			samsung,pin-function = <2>;
			samsung,pin-pud = <0>;
			samsung,pin-drv = <0>;
		};

		/* PERIC1 USI11_I2C */
		hsi2c27_bus: hsi2c27-bus {
			samsung,pins = "gpg3-5", "gpg3-6";
			samsung,pin-function = <3>;
			samsung,pin-pud = <0>;
			samsung,pin-drv = <0>;
		};

		/* PERIC1 CAM0 */
		spi0_bus: spi0-bus {
			samsung,pins = "gpc1-2", "gpc1-1", "gpc1-0";
			samsung,pin-function = <2>;
			samsung,pin-pud = <3>;
			samsung,pin-drv = <0>;
		};

		spi0_cs: spi0-cs {
			samsung,pins = "gpc1-3";
			samsung,pin-function = <1>;
			samsung,pin-pud = <3>;
			samsung,pin-drv = <0>;
		};

		spi0_cs_func: spi0-cs-func {
			samsung,pins = "gpc1-3";
			samsung,pin-function = <2>;
			samsung,pin-pud = <3>;
			samsung,pin-drv = <0>;
		};

		/* PERIC1 USI06_SPI */
		spi7_bus: spi7-bus {
			samsung,pins = "gpp4-2", "gpp4-1", "gpp4-0";
			samsung,pin-function = <2>;
			samsung,pin-pud = <3>;
			samsung,pin-drv = <0>;
		};

		spi7_cs: spi7-cs {
			samsung,pins = "gpp4-3";
			samsung,pin-function = <1>;
			samsung,pin-pud = <3>;
			samsung,pin-drv = <0>;
		};

		spi7_cs_func: spi7-cs-func {
			samsung,pins = "gpp4-3";
			samsung,pin-function = <2>;
			samsung,pin-pud = <3>;
			samsung,pin-drv = <0>;
		};

		/* PERIC1 USI07_SPI */
		spi8_bus: spi8-bus {
			samsung,pins = "gpp4-6", "gpp4-5", "gpp4-4";
			samsung,pin-function = <2>;
			samsung,pin-pud = <3>;
			samsung,pin-drv = <0>;
		};

		spi8_cs: spi8-cs {
			samsung,pins = "gpp4-7";
			samsung,pin-function = <1>;
			samsung,pin-pud = <3>;
			samsung,pin-drv = <0>;
		};

		spi8_cs_func: spi8-cs-func {
			samsung,pins = "gpp4-7";
			samsung,pin-function = <2>;
			samsung,pin-pud = <3>;
			samsung,pin-drv = <0>;
		};

		/* PERIC1 USI08_SPI */
		spi9_bus: spi9-bus {
			samsung,pins = "gpp5-2", "gpp5-1", "gpp5-0";
			samsung,pin-function = <2>;
			samsung,pin-pud = <3>;
			samsung,pin-drv = <0>;
		};

		spi9_cs: spi9-cs {
			samsung,pins = "gpp5-3";
			samsung,pin-function = <1>;
			samsung,pin-pud = <3>;
			samsung,pin-drv = <0>;
		};

		spi9_cs_func: spi9-cs-func {
			samsung,pins = "gpp5-3";
			samsung,pin-function = <2>;
			samsung,pin-pud = <3>;
			samsung,pin-drv = <0>;
		};

		/* PERIC1 USI09_SPI */
		spi10_bus: spi10-bus {
			samsung,pins = "gpp5-6", "gpp5-5", "gpp5-4";
			samsung,pin-function = <2>;
			samsung,pin-pud = <3>;
			samsung,pin-drv = <0>;
		};

		spi10_cs: spi10-cs {
			samsung,pins = "gpp5-7";
			samsung,pin-function = <1>;
			samsung,pin-pud = <3>;
			samsung,pin-drv = <0>;
		};

		spi10_cs_func: spi10-cs-func {
			samsung,pins = "gpp5-7";
			samsung,pin-function = <2>;
			samsung,pin-pud = <3>;
			samsung,pin-drv = <0>;
		};

		/* PERIC1 USI10_SPI */
		spi11_bus: spi11-bus {
			samsung,pins = "gpp6-2", "gpp6-1", "gpp6-0";
			samsung,pin-function = <2>;
			samsung,pin-pud = <3>;
			samsung,pin-drv = <0>;
		};

		spi11_cs: spi11-cs {
			samsung,pins = "gpp6-3";
			samsung,pin-function = <1>;
			samsung,pin-pud = <3>;
			samsung,pin-drv = <0>;
		};

		spi11_cs_func: spi11-cs-func {
			samsung,pins = "gpp6-3";
			samsung,pin-function = <2>;
			samsung,pin-pud = <3>;
			samsung,pin-drv = <0>;
		};

		/* PERIC1 USI11_SPI */
		spi12_bus: spi12-bus {
			samsung,pins = "gpg3-5", "gpg3-4", "gpg3-3";
			samsung,pin-function = <2>;
			samsung,pin-pud = <3>;
			samsung,pin-drv = <0>;
		};

		spi12_cs: spi12-cs {
			samsung,pins = "gpg3-6";
			samsung,pin-function = <1>;
			samsung,pin-pud = <3>;
			samsung,pin-drv = <0>;
		};

		spi12_cs_func: spi12-cs-func {
			samsung,pins = "gpg3-6";
			samsung,pin-function = <2>;
			samsung,pin-pud = <3>;
			samsung,pin-drv = <0>;
		};

		/* USI_PERIC1_USI06_UART */
		uart8_bus_single: uart8-bus {
			samsung,pins = "gpp4-3", "gpp4-2", "gpp4-1", "gpp4-0";
			samsung,pin-function = <2>;
			samsung,pin-pud = <0>;
		};

		/* USI_PERIC1_USI07_UART */
		uart9_bus_single: uart9-bus {
			samsung,pins = "gpp4-4", "gpp4-5", "gpp4-6", "gpp4-7";
			samsung,pin-function = <2>;
			samsung,pin-pud = <0>;
		};

		/* USI_PERIC1_USI08_UART */
		uart10_bus_single: uart10-bus {
			samsung,pins = "gpp5-3", "gpp5-2", "gpp5-1", "gpp5-0";
			samsung,pin-function = <2>;
			samsung,pin-pud = <0>;
		};

		/* USI_PERIC1_USI09_UART */
		uart11_bus_single: uart11-bus {
			samsung,pins = "gpp5-4", "gpp5-5", "gpp5-6", "gpp5-7";
			samsung,pin-function = <2>;
			samsung,pin-pud = <0>;
		};

		/* USI_PERIC1_USI10_UART */
		uart12_bus_single: uart12-bus {
			samsung,pins = "gpp6-3", "gpp6-2", "gpp6-1", "gpp6-0";
			samsung,pin-function = <2>;
			samsung,pin-pud = <0>;
		};

		/* USI_PERIC1_USI11_UART */
		uart13_bus_single: uart13-bus {
			samsung,pins = "gpg3-3", "gpg3-4", "gpg3-5", "gpg3-6";
			samsung,pin-function = <2>;
			samsung,pin-pud = <0>;
		};

		fimc_is_mclk0_in: fimc_is_mclk0_in {
			samsung,pins = "gpc1-4";
			samsung,pin-function = <0>;
			samsung,pin-pud = <0>;
			samsung,pin-drv = <0>;
		};

		fimc_is_mclk1_in: fimc_is_mclk1_in {
			samsung,pins = "gpc1-5";
			samsung,pin-function = <0>;
			samsung,pin-pud = <0>;
			samsung,pin-drv = <0>;
		};

		fimc_is_mclk2_in: fimc_is_mclk2_in {
			samsung,pins = "gpc1-6";
			samsung,pin-function = <0>;
			samsung,pin-pud = <0>;
			samsung,pin-drv = <1>;
		};

		fimc_is_mclk3_in: fimc_is_mclk3_in {
			samsung,pins = "gpc1-7";
			samsung,pin-function = <0>;
			samsung,pin-pud = <0>;
			samsung,pin-drv = <2>;
		};

		fimc_is_mclk0_out: fimc_is_mclk0_out {
			samsung,pins = "gpc1-4";
			samsung,pin-function = <1>;
			samsung,pin-pud = <1>;
			samsung,pin-drv = <0>;
		};

		fimc_is_mclk1_out: fimc_is_mclk1_out {
			samsung,pins = "gpc1-5";
			samsung,pin-function = <1>;
			samsung,pin-pud = <1>;
			samsung,pin-drv = <0>;
		};

		fimc_is_mclk2_out: fimc_is_mclk2_out {
			samsung,pins = "gpc1-6";
			samsung,pin-function = <1>;
			samsung,pin-pud = <1>;
			samsung,pin-drv = <1>;
		};

		fimc_is_mclk3_out: fimc_is_mclk3_out {
			samsung,pins = "gpc1-7";
			samsung,pin-function = <1>;
			samsung,pin-pud = <1>;
			samsung,pin-drv = <2>;
		};

		fimc_is_mclk0_fn: fimc_is_mclk0_fn {
			samsung,pins = "gpc1-4";
			samsung,pin-function = <2>;
			samsung,pin-pud = <0>;
			samsung,pin-drv = <0>;
		};

		fimc_is_mclk1_fn: fimc_is_mclk1_fn {
			samsung,pins = "gpc1-5";
			samsung,pin-function = <2>;
			samsung,pin-pud = <0>;
			samsung,pin-drv = <0>;
		};

		fimc_is_mclk2_fn: fimc_is_mclk2_fn {
			samsung,pins = "gpc1-6";
			samsung,pin-function = <2>;
			samsung,pin-pud = <0>;
			samsung,pin-drv = <1>;
		};

		fimc_is_mclk3_fn: fimc_is_mclk3_fn {
			samsung,pins = "gpc1-7";
			samsung,pin-function = <2>;
			samsung,pin-pud = <0>;
			samsung,pin-drv = <2>;
		};

		fimc_is_spi_pin0_out: fimc-is-spi-pin0-out {
			samsung,pins = "gpc1-2", "gpc1-1", "gpc1-0";
			samsung,pin-function = <1>;
			samsung,pin-pud = <1>;
			samsung,pin-drv = <0>;
			samsung,pin-val = <0>;
		};

		fimc_is_spi_pin0_fn: fimc-is-spi-pin0-fn {
			samsung,pins = "gpc1-2", "gpc1-1", "gpc1-0";
			samsung,pin-function = <2>;
			samsung,pin-pud = <0>;
			samsung,pin-drv = <0>;
			samsung,pin-val = <0>;
		};

		fimc_is_spi_ssn0_out: fimc-is-spi-ssn0-out {
			samsung,pins = "gpc1-3";
			samsung,pin-function = <1>;
			samsung,pin-pud = <1>;
			samsung,pin-drv = <0>;
			samsung,pin-val = <0>;
		};

		fimc_is_spi_ssn0_fn: fimc-is-spi-ssn0-fn {
			samsung,pins = "gpc1-3";
			samsung,pin-function = <2>;
			samsung,pin-pud = <0>;
			samsung,pin-drv = <0>;
		};

		fimc_is_spi_ssn0_inpd: fimc-is-spi-ssn0-inpd {
			samsung,pins = "gpc1-3";
			samsung,pin-function = <0>;
			samsung,pin-pud = <1>;
			samsung,pin-drv = <0>;
		};

		fimc_is_spi_ssn0_inpu: fimc-is-spi-ssn0-inpu {
			samsung,pins = "gpc1-3";
			samsung,pin-function = <0>;
			samsung,pin-pud = <3>;
			samsung,pin-drv = <0>;
		};
	};

	/* VTS */
	pinctrl@13880000 {
		gpt0: gpt0 {
			gpio-controller;
			#gpio-cells = <2>;

			interrupt-controller;
			#interrupt-cells = <2>;
		};

		dmic_bus_clk: dmic-bus-clk {
			samsung,pins = "gpt0-2";
			samsung,pin-function = <2>;
			samsung,pin-pud = <1>;
			sung,pin-con-pdn = <2>;
		};

		amic_bus_clk: amic-bus-clk {
			samsung,pins = "gpt0-2";
			samsung,pin-function = <2>;
			samsung,pin-pud = <0>;
			samsung,pin-con-pdn = <2>;
		};

		mic_bus_clk_idle: mic-bus-clk-idle {
			samsung,pins = "gpt0-2";
			samsung,pin-function = <0>;
			samsung,pin-pud = <0>;
			samsung,pin-con-pdn = <2>;
		};

		dmic_pdm: dmic-pdm {
			samsung,pins = "gpt0-1";
			samsung,pin-function = <2>;
			samsung,pin-pud = <1>;
			samsung,pin-con-pdn = <2>;
		};

		dmic_pdm_idle: dmic-pdm-idle {
			samsung,pins = "gpt0-1";
			samsung,pin-function = <0>;
			samsung,pin-pud = <0>;
			sung,pin-con-pdn = <2>;
		};

		amic_pdm: amic-pdm {
			samsung,pins = "gpt0-0";
			samsung,pin-function = <2>;
			samsung,pin-pud = <0>;
			samsung,pin-con-pdn = <2>;
		};

		amic_pdm_idle: amic-pdm-idle {
			samsung,pins = "gpt0-0";
			samsung,pin-function = <0>;
			samsung,pin-pud = <0>;
			samsung,pin-con-pdn = <2>;
		};
	};
};
